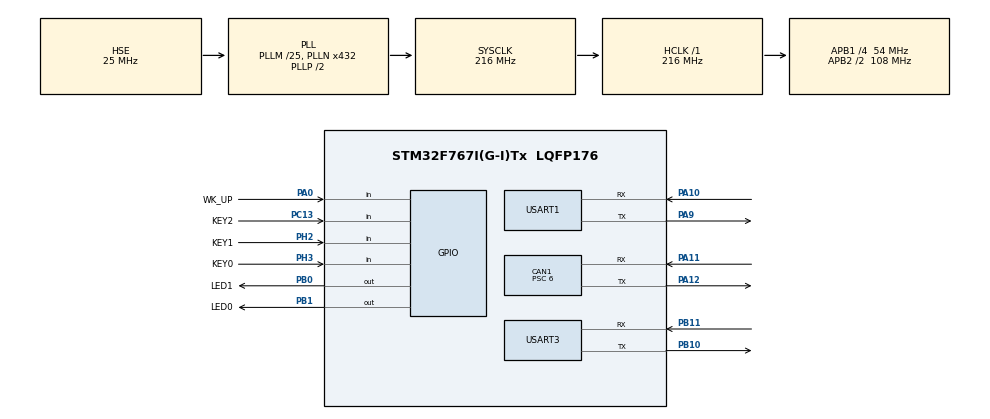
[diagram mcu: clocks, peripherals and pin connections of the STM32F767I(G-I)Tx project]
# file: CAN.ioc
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ADC1.Channel-0\#ChannelRegularConversion=ADC_CHANNEL_TEMPSENSOR
ADC1.NbrOfConversionFlag=1
ADC1.Rank-0\#ChannelRegularConversion=1
ADC1.SamplingTime-0\#ChannelRegularConversion=ADC_SAMPLETIME_3CYCLES
ADC1.master=1
CAN1.BS1=CAN_BS1_11TQ
CAN1.BS2=CAN_BS2_6TQ
CAN1.CalculateBaudRate=500000
CAN1.CalculateTimeBit=2000
CAN1.CalculateTimeQuantum=111.11111111111111
CAN1.Prescaler=6
CORTEX_M7.ART_ACCELERATOR_ENABLE=1
CORTEX_M7.CPU_DCache=Enabled
CORTEX_M7.CPU_ICache=Enabled
CORTEX_M7.PREFETCH_ENABLE=1
CORTEX_M7.default_mode_Activation=1
Mcu.Family=STM32F7
Mcu.Name=STM32F767I(G-I)Tx
Mcu.Package=LQFP176
NVIC.CAN1_RX0_IRQn=true\:0\:0\:true\:false\:true\:true\:true\:true
NVIC.PriorityGroup=NVIC_PRIORITYGROUP_4
NVIC.TIM2_IRQn=true\:0\:0\:false\:false\:true\:true\:true\:true
NVIC.USART3_IRQn=true\:0\:0\:false\:false\:true\:true\:true\:true
PA0/WKUP.GPIO_Label=WK_UP
PA0/WKUP.GPIO_PuPd=GPIO_PULLDOWN
PA0/WKUP.Signal=GPIO_Input
PA10.Mode=Asynchronous
PA10.Signal=USART1_RX
PA11.Mode=CAN_Activate
PA11.Signal=CAN1_RX
PA12.Mode=CAN_Activate
PA12.Signal=CAN1_TX
PA9.Mode=Asynchronous
PA9.Signal=USART1_TX
PB0.GPIO_Label=LED1
PB0.GPIO_PuPd=GPIO_PULLUP
PB0.GPIO_Speed=GPIO_SPEED_FREQ_VERY_HIGH
PB0.PinState=GPIO_PIN_RESET
PB0.Signal=GPIO_Output
PB1.GPIO_Label=LED0
PB1.GPIO_PuPd=GPIO_PULLUP
PB1.GPIO_Speed=GPIO_SPEED_FREQ_VERY_HIGH
PB1.PinState=GPIO_PIN_RESET
PB1.Signal=GPIO_Output
PB10.Mode=Asynchronous
PB10.Signal=USART3_TX
PB11.Mode=Asynchronous
PB11.Signal=USART3_RX
PC13.GPIO_Label=KEY2
PC13.GPIO_PuPd=GPIO_PULLUP
PC13.Signal=GPIO_Input
PH0/OSC_IN.Mode=HSE-External-Oscillator
PH0/OSC_IN.Signal=RCC_OSC_IN
PH1/OSC_OUT.Mode=HSE-External-Oscillator
PH1/OSC_OUT.Signal=RCC_OSC_OUT
PH2.GPIO_Label=KEY1
PH2.GPIO_PuPd=GPIO_PULLUP
PH2.Signal=GPIO_Input
PH3.GPIO_Label=KEY0
PH3.GPIO_PuPd=GPIO_PULLUP
PH3.Signal=GPIO_Input
ProjectManager.HeapSize=0x1000
ProjectManager.StackSize=0x1000
ProjectManager.TargetToolchain=MDK-ARM V5.32
RCC.AHBFreq_Value=216000000
RCC.APB1CLKDivider=RCC_HCLK_DIV4
RCC.APB1Freq_Value=54000000
RCC.APB1TimFreq_Value=108000000
RCC.APB2CLKDivider=RCC_HCLK_DIV2
RCC.APB2Freq_Value=108000000
RCC.APB2TimFreq_Value=216000000
RCC.CortexFreq_Value=216000000
RCC.HCLKFreq_Value=216000000
RCC.HSE_VALUE=25000000
RCC.HSI_VALUE=16000000
RCC.LSE_VALUE=32768
RCC.PLLM=25
RCC.PLLN=432
RCC.PLLSourceVirtual=RCC_PLLSOURCE_HSE
RCC.SYSCLKFreq_VALUE=216000000
RCC.SYSCLKSource=RCC_SYSCLKSOURCE_PLLCLK
RCC.USBFreq_Value=216000000
RCC.VCOOutputFreq_Value=432000000
TIM2.Period=1000-1
TIM2.Prescaler=108-1
USART1.VirtualMode-Asynchronous=VM_ASYNC
USART3.VirtualMode-Asynchronous=VM_ASYNC
VP_ADC1_TempSens_Input.Mode=IN-TempSens
VP_TIM2_VS_ClockSourceINT.Mode=Internal
board=custom

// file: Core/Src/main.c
/* USER CODE BEGIN Header */
/**
  ******************************************************************************
  * @file           : main.c
  * @brief          : Main program body
  ******************************************************************************
  * @attention
  *
  * Copyright (c) 2026 STMicroelectronics.
  * All rights reserved.
  *
  * This software is licensed under terms that can be found in the LICENSE file
  * in the root directory of this software component.
  * If no LICENSE file comes with this software, it is provided AS-IS.
  *
  ******************************************************************************
  */
/* USER CODE END Header */
#include "main.h"
#include "adc.h"
#include "can.h"
#include "tim.h"
#include "usart.h"
#include "gpio.h"

/* USER CODE BEGIN Includes */
#include "app.h"

/* USER CODE END Includes */

void SystemClock_Config(void);
static void MPU_Config(void);

int main(void)
{

  /* MPU Configuration--------------------------------------------------------*/
  MPU_Config();

  /* Enable the CPU Cache */

  /* Enable I-Cache---------------------------------------------------------*/
  SCB_EnableICache();

  /* Enable D-Cache---------------------------------------------------------*/
  SCB_EnableDCache();

  /* MCU Configuration--------------------------------------------------------*/

  /* Reset of all peripherals, Initializes the Flash interface and the Systick. */
  HAL_Init();

  /* Configure the system clock */
  SystemClock_Config();

  /* USER CODE BEGIN SysInit */
  /* Configure SysTick for one interrupt every 50 microseconds. */
  if (SysTick_Config(SystemCoreClock / 20000u) != 0u)
  {
    Error_Handler();
  }

  /* USART3 and SysTick both update the RTU receive context. Keeping them at
     the same preemption priority prevents either ISR from interrupting the
     other while preserving the existing interrupt-based architecture. */
  HAL_NVIC_SetPriority(SysTick_IRQn, 0u, 0u);

  /* USER CODE END SysInit */

  /* Initialize all configured peripherals */
  MX_GPIO_Init();
  MX_USART1_UART_Init();
  MX_ADC1_Init();
  MX_CAN1_Init();
  MX_TIM2_Init();
  MX_USART3_UART_Init();
  /* USER CODE BEGIN 2 */
  setup();
  app();

  /* USER CODE END 2 */

  /* Infinite loop */
  while (1)
  {

  }
}

void SystemClock_Config(void)
{
  RCC_OscInitTypeDef RCC_OscInitStruct = {0};
  RCC_ClkInitTypeDef RCC_ClkInitStruct = {0};

  /** Configure the main internal regulator output voltage
  */
  __HAL_RCC_PWR_CLK_ENABLE();
  __HAL_PWR_VOLTAGESCALING_CONFIG(PWR_REGULATOR_VOLTAGE_SCALE1);

  /** Initializes the RCC Oscillators according to the specified parameters
  * in the RCC_OscInitTypeDef structure.
  */
  RCC_OscInitStruct.OscillatorType = RCC_OSCILLATORTYPE_HSE;
  RCC_OscInitStruct.HSEState = RCC_HSE_ON;
  RCC_OscInitStruct.PLL.PLLState = RCC_PLL_ON;
  RCC_OscInitStruct.PLL.PLLSource = RCC_PLLSOURCE_HSE;
  RCC_OscInitStruct.PLL.PLLM = 25;
  RCC_OscInitStruct.PLL.PLLN = 432;
  RCC_OscInitStruct.PLL.PLLP = RCC_PLLP_DIV2;
  RCC_OscInitStruct.PLL.PLLQ = 2;
  RCC_OscInitStruct.PLL.PLLR = 2;
  if (HAL_RCC_OscConfig(&RCC_OscInitStruct) != HAL_OK)
  {
    Error_Handler();
  }

  /** Activate the Over-Drive mode
  */
  if (HAL_PWREx_EnableOverDrive() != HAL_OK)
  {
    Error_Handler();
  }

  /** Initializes the CPU, AHB and APB buses clocks
  */
  RCC_ClkInitStruct.ClockType = RCC_CLOCKTYPE_HCLK|RCC_CLOCKTYPE_SYSCLK
                              |RCC_CLOCKTYPE_PCLK1|RCC_CLOCKTYPE_PCLK2;
  RCC_ClkInitStruct.SYSCLKSource = RCC_SYSCLKSOURCE_PLLCLK;
  RCC_ClkInitStruct.AHBCLKDivider = RCC_SYSCLK_DIV1;
  RCC_ClkInitStruct.APB1CLKDivider = RCC_HCLK_DIV4;
  RCC_ClkInitStruct.APB2CLKDivider = RCC_HCLK_DIV2;

  if (HAL_RCC_ClockConfig(&RCC_ClkInitStruct, FLASH_LATENCY_7) != HAL_OK)
  {
    Error_Handler();
  }
}

/* USER CODE BEGIN 4 */
void Error_handler(void)
{
    while (1)
    {
        // Boucle infinie en cas d'erreur
    }
}

/* USER CODE END 4 */

 /* MPU Configuration */

void MPU_Config(void)
{
  MPU_Region_InitTypeDef MPU_InitStruct = {0};

  /* Disables the MPU */
  HAL_MPU_Disable();

  /** Initializes and configures the Region and the memory to be protected
  */
  MPU_InitStruct.Enable = MPU_REGION_ENABLE;
  MPU_InitStruct.Number = MPU_REGION_NUMBER0;
  MPU_InitStruct.BaseAddress = 0x0;
  MPU_InitStruct.Size = MPU_REGION_SIZE_4GB;
  MPU_InitStruct.SubRegionDisable = 0x87;
  MPU_InitStruct.TypeExtField = MPU_TEX_LEVEL0;
  MPU_InitStruct.AccessPermission = MPU_REGION_NO_ACCESS;
  MPU_InitStruct.DisableExec = MPU_INSTRUCTION_ACCESS_DISABLE;
  MPU_InitStruct.IsShareable = MPU_ACCESS_SHAREABLE;
  MPU_InitStruct.IsCacheable = MPU_ACCESS_NOT_CACHEABLE;
  MPU_InitStruct.IsBufferable = MPU_ACCESS_NOT_BUFFERABLE;

  HAL_MPU_ConfigRegion(&MPU_InitStruct);
  /* Enables the MPU */
  HAL_MPU_Enable(MPU_PRIVILEGED_DEFAULT);

}

void Error_Handler(void)
{
  __disable_irq();
  while (1)
  {
  }
}
